VERSION ""

NS_ :

BS_:

BU_:

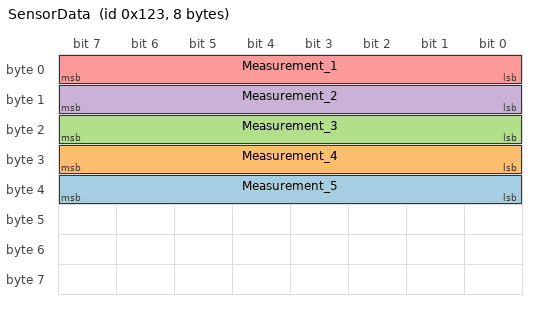
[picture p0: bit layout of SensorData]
BO_ 291 SensorData: 8 SensorNode
 SG_ Measurement_5 : 32|8@1+ (1,0) [0|0] "units" Vector__XXX
 SG_ Measurement_4 : 24|8@1+ (1,0) [0|0] "units" Vector__XXX
 SG_ Measurement_3 : 16|8@1+ (1,0) [0|0] "units" Vector__XXX
 SG_ Measurement_2 : 8|8@1+ (1,0) [0|0] "units" Vector__XXX
 SG_ Measurement_1 : 0|8@1+ (1,0) [0|0] "units" Vector__XXX

BA_DEF_ SG_  "GenSigStartValue" FLOAT 0 100000000000;
BA_DEF_DEF_  "GenSigStartValue" 0;
